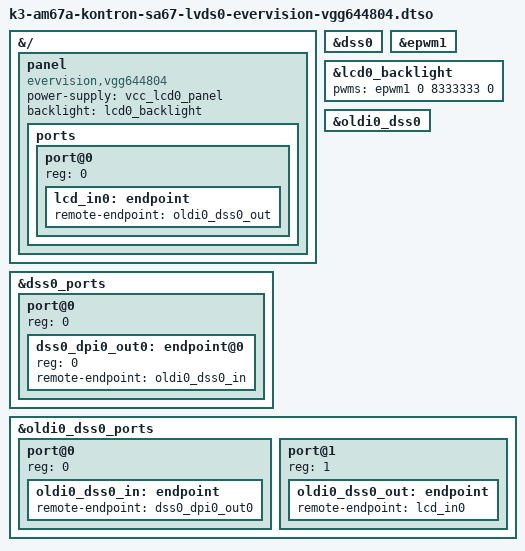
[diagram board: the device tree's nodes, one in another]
/dts-v1/;
/plugin/;

&{/} {
	panel {
		compatible = "evervision,vgg644804";
		power-supply = <&vcc_lcd0_panel>;
		backlight = <&lcd0_backlight>;

		ports {
			#address-cells = <1>;
			#size-cells = <0>;

			port@0 {
				reg = <0>;

				lcd_in0: endpoint {
					remote-endpoint = <&oldi0_dss0_out>;
				};
			};
		};
	};
};

&dss0 {
	status = "okay";
};

&dss0_ports {
	#address-cells = <1>;
	#size-cells = <0>;

	port@0 {
		reg = <0>;
		#address-cells = <1>;
		#size-cells = <0>;

		dss0_dpi0_out0: endpoint@0 {
			reg = <0>;
			remote-endpoint = <&oldi0_dss0_in>;
		};
	};
};

&epwm1 {
	status = "okay";
};

&lcd0_backlight {
	status = "okay";
	pwms = <&epwm1 0 8333333 0>;
};

&oldi0_dss0 {
	status = "okay";
};

&oldi0_dss0_ports {
	#address-cells = <1>;
	#size-cells = <0>;

	port@0 {
		reg = <0>;

		oldi0_dss0_in: endpoint {
			remote-endpoint = <&dss0_dpi0_out0>;
		};
	};

	port@1 {
		reg = <1>;

		oldi0_dss0_out: endpoint {
			remote-endpoint = <&lcd_in0>;
		};
	};
};
